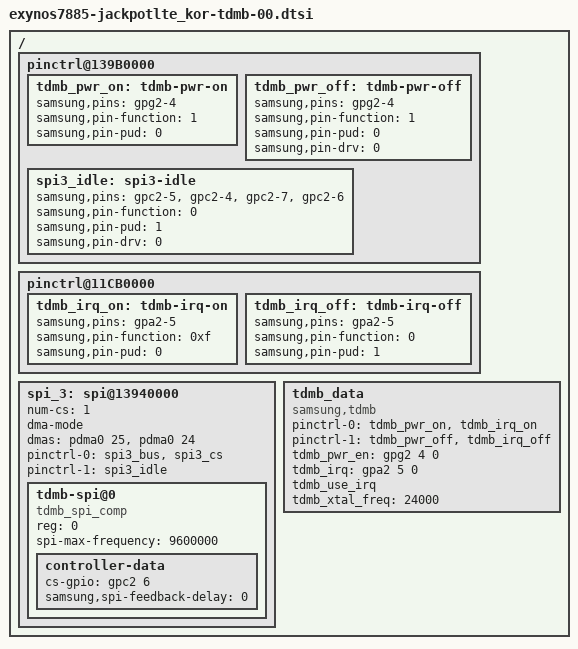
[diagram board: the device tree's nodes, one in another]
 /* Copyright (c) 2012-2014, The Linux Foundation. All rights reserved.
 *
 * This program is free software; you can redistribute it and/or modify
 * it under the terms of the GNU General Public License version 2 and
 * only version 2 as published by the Free Software Foundation.
 *
 * This program is distributed in the hope that it will be useful,
 * but WITHOUT ANY WARRANTY; without even the implied warranty of
 * MERCHANTABILITY or FITNESS FOR A PARTICULAR PURPOSE.  See the
 * GNU General Public License for more details.
 */

/{
	pinctrl@139B0000 {
		tdmb_pwr_on: tdmb-pwr-on {
			samsung,pins = "gpg2-4";
			samsung,pin-function = <1>;
			samsung,pin-pud = <0>;
		};
		tdmb_pwr_off: tdmb-pwr-off {
			samsung,pins = "gpg2-4";
			samsung,pin-function = <1>;
			samsung,pin-pud = <0>;
			samsung,pin-drv = <0>;
		};
	};

	pinctrl@11CB0000 {
		tdmb_irq_on: tdmb-irq-on {
			samsung,pins = "gpa2-5";
			samsung,pin-function = <0xf>;
			samsung,pin-pud = <0>;
		};
		tdmb_irq_off: tdmb-irq-off {
			samsung,pins = "gpa2-5";
			samsung,pin-function = <0>;
			samsung,pin-pud = <1>;
		};
	};

	pinctrl@139B0000 {
		spi3_idle: spi3-idle {
			samsung,pins = "gpc2-5", "gpc2-4", "gpc2-7", "gpc2-6";
			samsung,pin-function = <0>;
			samsung,pin-pud = <1>;
			samsung,pin-drv = <0>;
		};
	};

	spi_3: spi@13940000 {
		#address-cells = <1>;
		#size-cells = <0>;
		num-cs = <1>;

		dma-mode;
		dmas = <&pdma0 25
			&pdma0 24>;
		dma-names = "tx", "rx";

		status = "ok";

		pinctrl-names = "default", "idle";
		pinctrl-0 = <&spi3_bus &spi3_cs>;
		pinctrl-1 = <&spi3_idle>;

		tdmb-spi@0 {
			compatible = "tdmb_spi_comp";
			reg = <0>;
			spi-max-frequency = <9600000>;
			controller-data {
				cs-gpio = <&gpc2 6 0>;
				samsung,spi-feedback-delay = <0>;
			};
		};
	};

	tdmb_data {
		compatible = "samsung,tdmb";
		pinctrl-names = "tdmb_on", "tdmb_off";
		pinctrl-0 = <&tdmb_pwr_on &tdmb_irq_on>;
		pinctrl-1 = <&tdmb_pwr_off &tdmb_irq_off>;
		tdmb_pwr_en = <&gpg2 4 0>;
		tdmb_irq = <&gpa2 5 0>;
		tdmb_use_irq;
		tdmb_xtal_freq = <24000>;
	};

};
